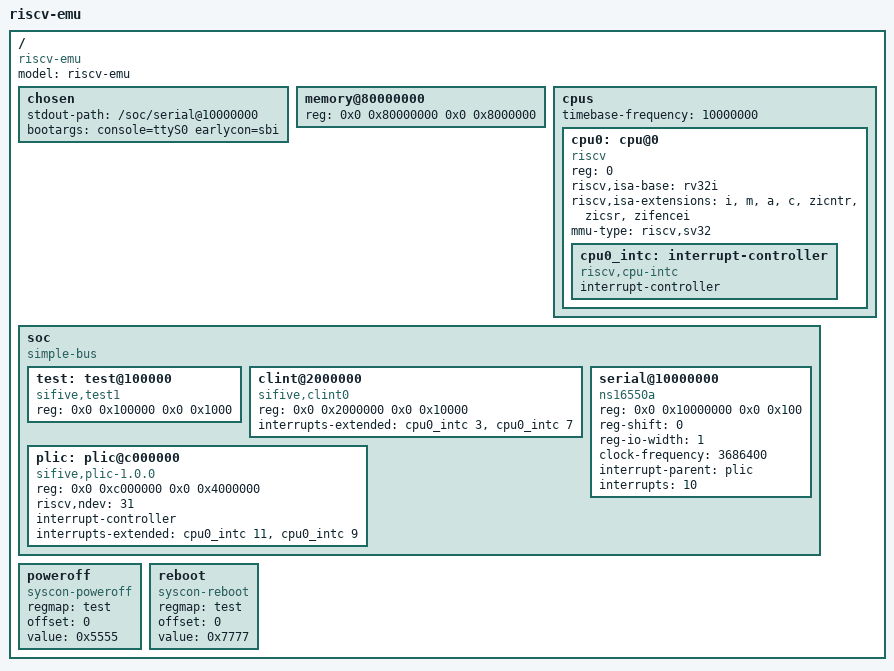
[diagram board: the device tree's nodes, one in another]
/dts-v1/;

// The device tree of the riscv-emu machine, modelled on QEMU's virt machine (two address and size cells even on RV32, as
// QEMU does). Every address, size and interrupt number here is checked against the emulator's headers by tests/check-dts.sh.
// The finisher device (test@100000) is described now and implemented in a later task.

/ {
	#address-cells = <2>;
	#size-cells = <2>;
	compatible = "riscv-emu";
	model = "riscv-emu";

	chosen {
		stdout-path = "/soc/serial@10000000";
		// console=ttyS0: the 16550 is the console. earlycon=sbi: print through OpenSBI from the very first kernel message,
		// before the UART driver is up. The root filesystem is an initramfs linked into the kernel, whose /init is found by
		// default, so there is no root= or rdinit=.
		bootargs = "console=ttyS0 earlycon=sbi";
	};

	memory@80000000 {
		device_type = "memory";
		reg = <0x0 0x80000000 0x0 0x8000000>;
	};

	cpus {
		#address-cells = <1>;
		#size-cells = <0>;
		timebase-frequency = <10000000>;

		cpu0: cpu@0 {
			device_type = "cpu";
			reg = <0>;
			status = "okay";
			compatible = "riscv";
			riscv,isa-base = "rv32i";
			riscv,isa-extensions = "i", "m", "a", "c", "zicntr", "zicsr", "zifencei";
			mmu-type = "riscv,sv32";

			cpu0_intc: interrupt-controller {
				#interrupt-cells = <1>;
				interrupt-controller;
				compatible = "riscv,cpu-intc";
			};
		};
	};

	soc {
		#address-cells = <2>;
		#size-cells = <2>;
		compatible = "simple-bus";
		ranges;

		test: test@100000 {
			compatible = "sifive,test1", "sifive,test0", "syscon";
			reg = <0x0 0x100000 0x0 0x1000>;
		};

		clint@2000000 {
			compatible = "sifive,clint0", "riscv,clint0";
			reg = <0x0 0x2000000 0x0 0x10000>;
			interrupts-extended = <&cpu0_intc 3>, <&cpu0_intc 7>;
		};

		// The order of interrupts-extended is the context number: 0 is hart 0 in M-mode, 1 is hart 0 in S-mode
		plic: plic@c000000 {
			compatible = "sifive,plic-1.0.0", "riscv,plic0";
			reg = <0x0 0xc000000 0x0 0x4000000>;
			riscv,ndev = <31>;
			interrupt-controller;
			#address-cells = <0>;
			#interrupt-cells = <1>;
			interrupts-extended = <&cpu0_intc 11>, <&cpu0_intc 9>;
		};

		serial@10000000 {
			compatible = "ns16550a";
			reg = <0x0 0x10000000 0x0 0x100>;
			reg-shift = <0>;
			reg-io-width = <1>;
			clock-frequency = <3686400>;
			interrupt-parent = <&plic>;
			interrupts = <10>;
		};
	};

	poweroff {
		compatible = "syscon-poweroff";
		regmap = <&test>;
		offset = <0>;
		value = <0x5555>;
	};

	reboot {
		compatible = "syscon-reboot";
		regmap = <&test>;
		offset = <0>;
		value = <0x7777>;
	};
};
